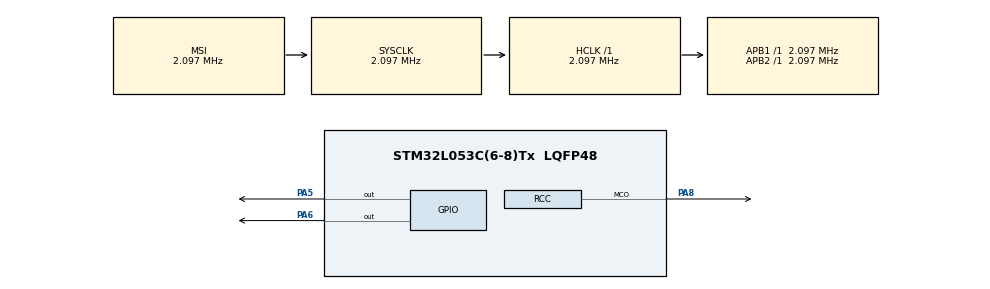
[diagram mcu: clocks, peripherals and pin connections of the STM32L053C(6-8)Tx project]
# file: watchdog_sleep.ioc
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IWDG.Prescaler=IWDG_PRESCALER_256
IWDG.Reload=180
Mcu.Family=STM32L0
Mcu.Name=STM32L053C(6-8)Tx
Mcu.Package=LQFP48
PA13.Mode=Serial_Wire
PA13.Signal=SYS_SWDIO
PA14.Mode=Serial_Wire
PA14.Signal=SYS_SWCLK
PA5.Signal=GPIO_Output
PA6.Signal=GPIO_Output
PA8.Mode=Clock-out
PA8.Signal=RCC_MCO
ProjectManager.HeapSize=0x200
ProjectManager.StackSize=0x400
ProjectManager.TargetToolchain=SW4STM32
RCC.AHBFreq_Value=2097000
RCC.APB1Freq_Value=2097000
RCC.APB1TimFreq_Value=2097000
RCC.APB2Freq_Value=2097000
RCC.APB2TimFreq_Value=2097000
RCC.HSE_VALUE=8000000
RCC.HSI16_VALUE=16000000
RCC.HSI48_VALUE=48000000
RCC.HSI_VALUE=16000000
RCC.LSE_VALUE=32768
RCC.MSI_VALUE=2097000
RCC.RCC_MCOSource=RCC_MCO1SOURCE_LSI
RCC.SYSCLKFreq_VALUE=2097000
RCC.VCOOutputFreq_Value=48000000
VP_IWDG_VS_IWDG.Mode=IWDG_Activate
board=watchdog_sleep

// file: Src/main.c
/**
  ******************************************************************************
  * File Name          : main.c
  * Description        : Main program body
  ******************************************************************************
  ** This notice applies to any and all portions of this file
  * that are not between comment pairs USER CODE BEGIN and
  * USER CODE END. Other portions of this file, whether
  * inserted by the user or by software development tools
  * are owned by their respective copyright owners.
  *
  * COPYRIGHT(c) 2017 STMicroelectronics
  *
  * Redistribution and use in source and binary forms, with or without modification,
  * are permitted provided that the following conditions are met:
  *   1. Redistributions of source code must retain the above copyright notice,
  *      this list of conditions and the following disclaimer.
  *   2. Redistributions in binary form must reproduce the above copyright notice,
  *      this list of conditions and the following disclaimer in the documentation
  *      and/or other materials provided with the distribution.
  *   3. Neither the name of STMicroelectronics nor the names of its contributors
  *      may be used to endorse or promote products derived from this software
  *      without specific prior written permission.
  *
  * THIS SOFTWARE IS PROVIDED BY THE COPYRIGHT HOLDERS AND CONTRIBUTORS "AS IS"
  * AND ANY EXPRESS OR IMPLIED WARRANTIES, INCLUDING, BUT NOT LIMITED TO, THE
  * IMPLIED WARRANTIES OF MERCHANTABILITY AND FITNESS FOR A PARTICULAR PURPOSE ARE
  * DISCLAIMED. IN NO EVENT SHALL THE COPYRIGHT HOLDER OR CONTRIBUTORS BE LIABLE
  * FOR ANY DIRECT, INDIRECT, INCIDENTAL, SPECIAL, EXEMPLARY, OR CONSEQUENTIAL
  * DAMAGES (INCLUDING, BUT NOT LIMITED TO, PROCUREMENT OF SUBSTITUTE GOODS OR
  * SERVICES; LOSS OF USE, DATA, OR PROFITS; OR BUSINESS INTERRUPTION) HOWEVER
  * CAUSED AND ON ANY THEORY OF LIABILITY, WHETHER IN CONTRACT, STRICT LIABILITY,
  * OR TORT (INCLUDING NEGLIGENCE OR OTHERWISE) ARISING IN ANY WAY OUT OF THE USE
  * OF THIS SOFTWARE, EVEN IF ADVISED OF THE POSSIBILITY OF SUCH DAMAGE.
  *
  ******************************************************************************
  */
#include "main.h"
#include "stm32l0xx_hal.h"
#include "iwdg.h"
#include "gpio.h"

/* USER CODE BEGIN PV */
/* Private variables ---------------------------------------------------------*/

/* USER CODE END PV */

void SystemClock_Config(void);

/* USER CODE BEGIN PFP */
/* Private function prototypes -----------------------------------------------*/

/* USER CODE END PFP */

int main(void)
{

  /* MCU Configuration----------------------------------------------------------*/

  /* Reset of all peripherals, Initializes the Flash interface and the Systick. */
  HAL_Init();

  /* Configure the system clock */
  SystemClock_Config();

  /* Initialize all configured peripherals */
  MX_GPIO_Init();
  MX_IWDG_Init();

  /* USER CODE BEGIN 2 */
  HAL_GPIO_WritePin(GPIOA, GPIO_PIN_5, GPIO_PIN_SET);

  /* USER CODE END 2 */

  /* Infinite loop */
  while (1)
  {

  /* USER CODE BEGIN 3 */

      HAL_Delay(500);
      HAL_GPIO_WritePin(GPIOA, GPIO_PIN_5, GPIO_PIN_RESET);

      // Watchdog will reset once its timer runs out
      // unless it is refreshed with the following line uncommented:
      //HAL_IWDG_Refresh(&hiwdg);

  }
  /* USER CODE END 3 */

}

/** System Clock Configuration
*/
void SystemClock_Config(void)
{

  RCC_OscInitTypeDef RCC_OscInitStruct;
  RCC_ClkInitTypeDef RCC_ClkInitStruct;

    /**Configure the main internal regulator output voltage
    */
  __HAL_PWR_VOLTAGESCALING_CONFIG(PWR_REGULATOR_VOLTAGE_SCALE1);

    /**Initializes the CPU, AHB and APB busses clocks
    */
  RCC_OscInitStruct.OscillatorType = RCC_OSCILLATORTYPE_LSI|RCC_OSCILLATORTYPE_MSI;
  RCC_OscInitStruct.LSIState = RCC_LSI_ON;
  RCC_OscInitStruct.MSIState = RCC_MSI_ON;
  RCC_OscInitStruct.MSICalibrationValue = 0;
  RCC_OscInitStruct.MSIClockRange = RCC_MSIRANGE_5;
  RCC_OscInitStruct.PLL.PLLState = RCC_PLL_NONE;
  if (HAL_RCC_OscConfig(&RCC_OscInitStruct) != HAL_OK)
  {
    _Error_Handler(__FILE__, __LINE__);
  }

    /**Initializes the CPU, AHB and APB busses clocks
    */
  RCC_ClkInitStruct.ClockType = RCC_CLOCKTYPE_HCLK|RCC_CLOCKTYPE_SYSCLK
                              |RCC_CLOCKTYPE_PCLK1|RCC_CLOCKTYPE_PCLK2;
  RCC_ClkInitStruct.SYSCLKSource = RCC_SYSCLKSOURCE_MSI;
  RCC_ClkInitStruct.AHBCLKDivider = RCC_SYSCLK_DIV1;
  RCC_ClkInitStruct.APB1CLKDivider = RCC_HCLK_DIV1;
  RCC_ClkInitStruct.APB2CLKDivider = RCC_HCLK_DIV1;

  if (HAL_RCC_ClockConfig(&RCC_ClkInitStruct, FLASH_LATENCY_0) != HAL_OK)
  {
    _Error_Handler(__FILE__, __LINE__);
  }

  HAL_RCC_MCOConfig(RCC_MCO1, RCC_MCO1SOURCE_LSI, RCC_MCODIV_1);

    /**Configure the Systick interrupt time
    */
  HAL_SYSTICK_Config(HAL_RCC_GetHCLKFreq()/1000);

    /**Configure the Systick
    */
  HAL_SYSTICK_CLKSourceConfig(SYSTICK_CLKSOURCE_HCLK);

  /* SysTick_IRQn interrupt configuration */
  HAL_NVIC_SetPriority(SysTick_IRQn, 0, 0);
}

void _Error_Handler(char * file, int line)
{
  while(1)
  {
  }
}

/************************ (C) COPYRIGHT STMicroelectronics *****END OF FILE****/
